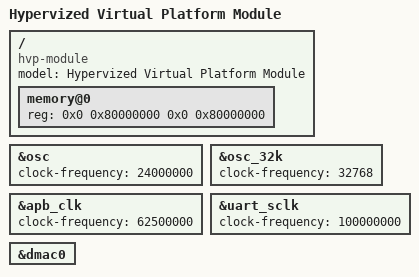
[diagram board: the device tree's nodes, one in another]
// SPDX-License-Identifier: (GPL-2.0 OR MIT)
/*
 * Copyright (C) 2024 Haicheng Li <haicheng.li@intel.com>
 */

/dts-v1/;

#include "virt.dtsi"

/ {
	model = "Hypervized Virtual Platform Module";
	compatible = "hvp-module", "intel,hvp";

	memory@0 {
		device_type = "memory";
		reg = <0x0 0x80000000 0x0 0x80000000>;
	};
};

&osc {
	clock-frequency = <24000000>;
};

&osc_32k {
	clock-frequency = <32768>;
};

&apb_clk {
	clock-frequency = <62500000>;
};

&uart_sclk {
	clock-frequency = <100000000>;
};

&dmac0 {
	status = "okay";
};
